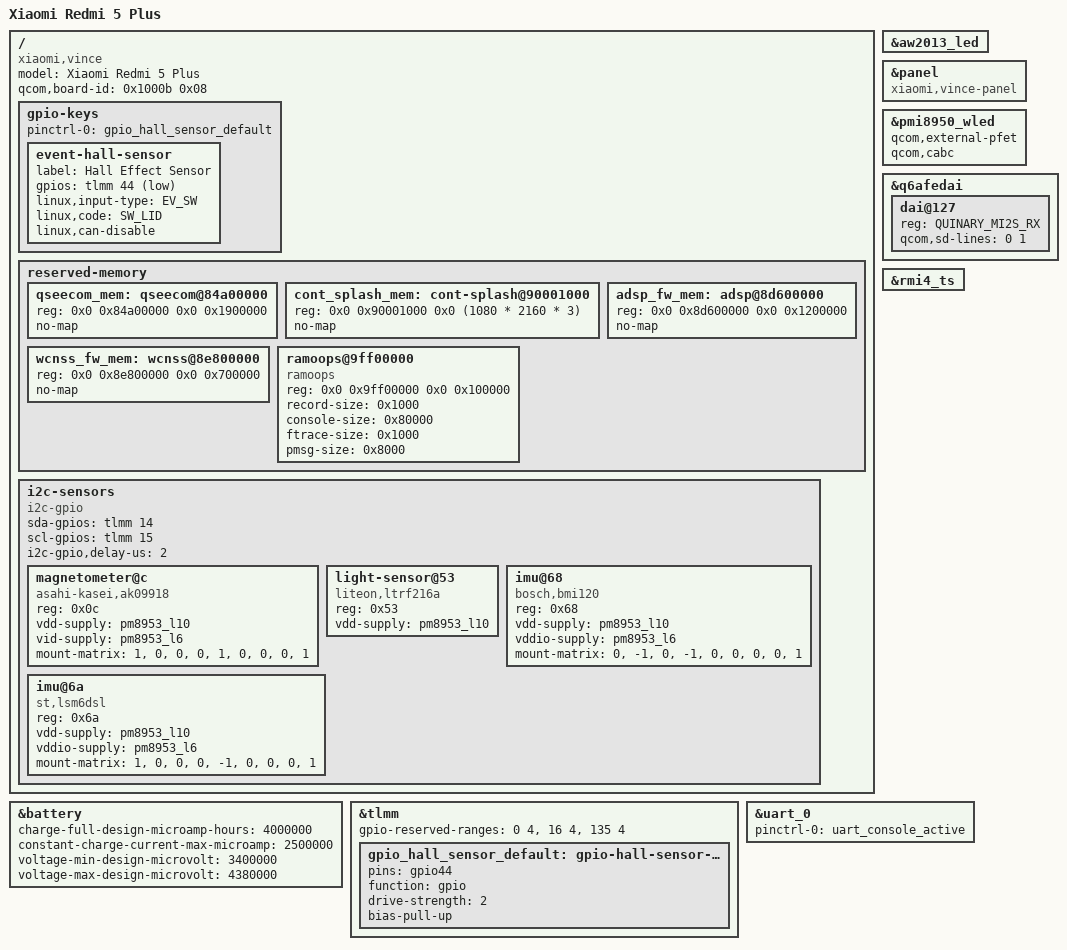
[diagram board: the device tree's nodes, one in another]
// SPDX-License-Identifier: BSD-3-Clause
/*
 * Copyright (c) 2022, Eugene Lepshy <fekz115@gmail.com>
 * Copyright (c) 2022, Gianluca Boiano <morf3089@gmail.com>
 */
/dts-v1/;

#include "msm8953-xiaomi-common.dtsi"

/delete-node/ &adsp_fw_mem;
/delete-node/ &cont_splash_mem;
/delete-node/ &qseecom_mem;
/delete-node/ &wcnss_fw_mem;

/ {
	model = "Xiaomi Redmi 5 Plus";
	compatible = "xiaomi,vince", "qcom,msm8953";
	qcom,board-id = <0x1000b 0x08>;

	gpio-keys {
		pinctrl-names = "default";
		pinctrl-0 = <&gpio_hall_sensor_default>;

		event-hall-sensor {
			label = "Hall Effect Sensor";
			gpios = <&tlmm 44 GPIO_ACTIVE_LOW>;
			linux,input-type = <EV_SW>;
			linux,code = <SW_LID>;
			linux,can-disable;
		};
	};

	reserved-memory {
		qseecom_mem: qseecom@84a00000 {
			reg = <0x0 0x84a00000 0x0 0x1900000>;
			no-map;
		};

		cont_splash_mem: cont-splash@90001000 {
			reg = <0x0 0x90001000 0x0 (1080 * 2160 * 3)>;
			no-map;
		};

		adsp_fw_mem: adsp@8d600000 {
			reg = <0x0 0x8d600000 0x0 0x1200000>;
			no-map;
		};

		wcnss_fw_mem: wcnss@8e800000 {
			reg = <0x0 0x8e800000 0x0 0x700000>;
			no-map;
		};

		ramoops@9ff00000 {
			compatible = "ramoops";
			reg = <0x0 0x9ff00000 0x0 0x100000>;
			record-size = <0x1000>;
			console-size = <0x80000>;
			ftrace-size = <0x1000>;
			pmsg-size = <0x8000>;
		};
	};

	/*
	 * We bitbang on &i2c_4 because BLSP is protected by TZ as sensors are
	 * normally proxied via ADSP firmware. GPIOs aren't protected.
	 */
	i2c-sensors {
		compatible = "i2c-gpio";
		sda-gpios = <&tlmm 14 (GPIO_ACTIVE_HIGH|GPIO_OPEN_DRAIN)>;
		scl-gpios = <&tlmm 15 (GPIO_ACTIVE_HIGH|GPIO_OPEN_DRAIN)>;
		i2c-gpio,delay-us = <2>; /* ~100 kHz */
		#address-cells = <1>;
		#size-cells = <0>;

		magnetometer@c {
			compatible = "asahi-kasei,ak09918";
			reg = <0x0c>;
			vdd-supply = <&pm8953_l10>;
			vid-supply = <&pm8953_l6>;
			mount-matrix = "1", "0", "0",
					"0", "1", "0",
					"0", "0", "1";
		};

		light-sensor@53 {
			compatible = "liteon,ltrf216a";
			reg = <0x53>;
			vdd-supply = <&pm8953_l10>;
		};

		imu@68 {
			compatible = "bosch,bmi120";
			reg = <0x68>;

			vdd-supply = <&pm8953_l10>;
			vddio-supply = <&pm8953_l6>;

			mount-matrix = "0", "-1", "0",
					"-1", "0", "0",
					"0", "0", "1";
		};

		imu@6a {
			compatible = "st,lsm6dsl";
			reg = <0x6a>;
			vdd-supply = <&pm8953_l10>;
			vddio-supply = <&pm8953_l6>;
			mount-matrix = "1", "0", "0",
					"0", "-1", "0",
					"0", "0", "1";
		};
	};
};

&aw2013_led {
	status = "okay";
};

&battery {
	charge-full-design-microamp-hours = <4000000>;
	constant-charge-current-max-microamp = <2500000>;
	voltage-min-design-microvolt = <3400000>;
	voltage-max-design-microvolt = <4380000>;
};

&panel {
	compatible = "xiaomi,vince-panel";
};

&pmi8950_wled {
	qcom,external-pfet;
	qcom,cabc;
};

&q6afedai {
	dai@127 {
		reg = <QUINARY_MI2S_RX>;
		qcom,sd-lines = <0 1>;
	};
};

&rmi4_ts {
	status = "okay";
};

&tlmm {
	gpio-reserved-ranges = <0 4>, <16 4>, <135 4>;

	gpio_hall_sensor_default: gpio-hall-sensor-state {
		pins = "gpio44";
		function = "gpio";
		drive-strength = <2>;
		bias-pull-up;
	};
};

&uart_0 {
	pinctrl-names = "default";
	pinctrl-0 = <&uart_console_active>;

	status = "okay";
};
